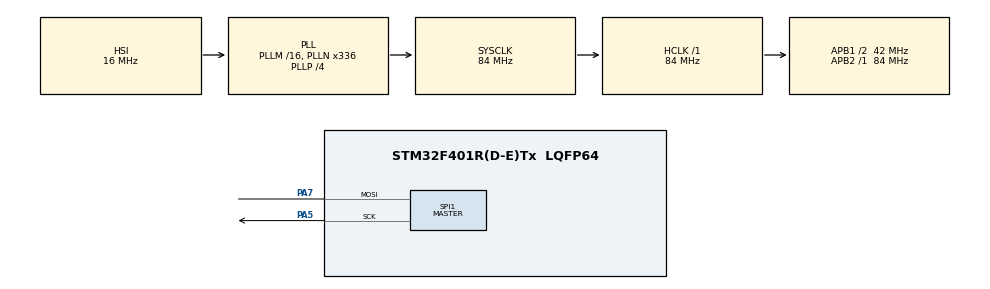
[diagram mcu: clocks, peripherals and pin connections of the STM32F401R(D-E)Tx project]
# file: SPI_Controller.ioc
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Mcu.Family=STM32F4
Mcu.Name=STM32F401R(D-E)Tx
Mcu.Package=LQFP64
NVIC.PriorityGroup=NVIC_PRIORITYGROUP_0
PA5.Mode=Simplex_Bidirectional_Master
PA5.Signal=SPI1_SCK
PA7.Mode=Simplex_Bidirectional_Master
PA7.Signal=SPI1_MOSI
ProjectManager.HeapSize=0x200
ProjectManager.StackSize=0x400
ProjectManager.TargetToolchain=STM32CubeIDE
RCC.48MHZClocksFreq_Value=48000000
RCC.AHBFreq_Value=84000000
RCC.APB1CLKDivider=RCC_HCLK_DIV2
RCC.APB1Freq_Value=42000000
RCC.APB1TimFreq_Value=84000000
RCC.APB2Freq_Value=84000000
RCC.APB2TimFreq_Value=84000000
RCC.CortexFreq_Value=84000000
RCC.HCLKFreq_Value=84000000
RCC.HSE_VALUE=8000000
RCC.HSI_VALUE=16000000
RCC.LSE_VALUE=32768
RCC.PLLN=336
RCC.PLLP=RCC_PLLP_DIV4
RCC.PLLQ=7
RCC.SYSCLKFreq_VALUE=84000000
RCC.SYSCLKSource=RCC_SYSCLKSOURCE_PLLCLK
RCC.VCOOutputFreq_Value=336000000
SPI1.Direction=SPI_DIRECTION_1LINE
SPI1.Mode=SPI_MODE_MASTER
SPI1.VirtualType=VM_MASTER
board=NUCLEO-F401RE

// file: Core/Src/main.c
/* USER CODE BEGIN Header */
/**
  ******************************************************************************
  * @file           : main.c
  * @brief          : Main program body
  ******************************************************************************
  * @attention
  *
  * Copyright (c) 2024 STMicroelectronics.
  * All rights reserved.
  *
  * This software is licensed under terms that can be found in the LICENSE file
  * in the root directory of this software component.
  * If no LICENSE file comes with this software, it is provided AS-IS.
  *
  ******************************************************************************
  */
/* USER CODE END Header */
#include "main.h"

/* USER CODE BEGIN Includes */
#include <string.h>

/* USER CODE END Includes */

SPI_HandleTypeDef hspi1;

void SystemClock_Config(void);
static void MX_GPIO_Init(void);
static void MX_SPI1_Init(void);

int main(void)
{

  /* MCU Configuration--------------------------------------------------------*/

  /* Reset of all peripherals, Initializes the Flash interface and the Systick. */
  HAL_Init();

  /* Configure the system clock */
  SystemClock_Config();

  /* Initialize all configured peripherals */
  MX_GPIO_Init();
  MX_SPI1_Init();

  /* Infinite loop */
  /* USER CODE BEGIN WHILE */
  char data[5] = "";
  uint8_t len_req = 0x3;
  uint8_t data_req = 0x2;
  uint8_t temp = 0x0;

  //(void)HAL_SPI_Transmit(&hspi1, &data, 1, 100000);

  //lets confirm SPI is not busy
 //while( ( SPI1->SR & SPI_SR_BSY ) == 1 );

  //for(int i = 0; i < 10000; i++) {};

  //lets confirm SPI is not busy
  //while( ( SPI1->SR & SPI_SR_BSY ) == 1 );
  //for(int i = 0; i < 10000000; i++) {};
  //(void)HAL_SPI_Transmit(&hspi1, &data_req, 1, 100000);
  //while( ( SPI1->SR & SPI_SR_BSY ) == 1 );

  SPI2->CR1 &= ~( 1 << SPI_CR1_SPE );
  SPI2->CR1 |= ( 1 << SPI_CR1_BIDIOE );
  SPI2->CR1 |= ( 1 << SPI_CR1_SPE );
  (void)HAL_SPI_Transmit(&hspi1, &len_req, 1, 100000);

  SPI2->CR1 &= ~( 1 << SPI_CR1_SPE );
  SPI2->CR1 &= ~( 1 << SPI_CR1_BIDIOE );
  SPI2->CR1 |= ( 1 << SPI_CR1_SPE );

  for(int i = 0; i < 10000000; i++) {};
  (void)HAL_SPI_Receive(&hspi1, (uint8_t *)data, 5, 100000);
  while( ( SPI1->SR & SPI_SR_BSY ) == 1 );

  while (1)
  {

    /* USER CODE END WHILE */

  }
}

void SystemClock_Config(void)
{
  RCC_OscInitTypeDef RCC_OscInitStruct = {0};
  RCC_ClkInitTypeDef RCC_ClkInitStruct = {0};

  /** Configure the main internal regulator output voltage
  */
  __HAL_RCC_PWR_CLK_ENABLE();
  __HAL_PWR_VOLTAGESCALING_CONFIG(PWR_REGULATOR_VOLTAGE_SCALE2);

  /** Initializes the RCC Oscillators according to the specified parameters
  * in the RCC_OscInitTypeDef structure.
  */
  RCC_OscInitStruct.OscillatorType = RCC_OSCILLATORTYPE_HSI;
  RCC_OscInitStruct.HSIState = RCC_HSI_ON;
  RCC_OscInitStruct.HSICalibrationValue = RCC_HSICALIBRATION_DEFAULT;
  RCC_OscInitStruct.PLL.PLLState = RCC_PLL_ON;
  RCC_OscInitStruct.PLL.PLLSource = RCC_PLLSOURCE_HSI;
  RCC_OscInitStruct.PLL.PLLM = 16;
  RCC_OscInitStruct.PLL.PLLN = 336;
  RCC_OscInitStruct.PLL.PLLP = RCC_PLLP_DIV4;
  RCC_OscInitStruct.PLL.PLLQ = 7;
  if (HAL_RCC_OscConfig(&RCC_OscInitStruct) != HAL_OK)
  {
    Error_Handler();
  }

  /** Initializes the CPU, AHB and APB buses clocks
  */
  RCC_ClkInitStruct.ClockType = RCC_CLOCKTYPE_HCLK|RCC_CLOCKTYPE_SYSCLK
                              |RCC_CLOCKTYPE_PCLK1|RCC_CLOCKTYPE_PCLK2;
  RCC_ClkInitStruct.SYSCLKSource = RCC_SYSCLKSOURCE_PLLCLK;
  RCC_ClkInitStruct.AHBCLKDivider = RCC_SYSCLK_DIV1;
  RCC_ClkInitStruct.APB1CLKDivider = RCC_HCLK_DIV2;
  RCC_ClkInitStruct.APB2CLKDivider = RCC_HCLK_DIV1;

  if (HAL_RCC_ClockConfig(&RCC_ClkInitStruct, FLASH_LATENCY_2) != HAL_OK)
  {
    Error_Handler();
  }
}

static void MX_SPI1_Init(void)
{

  /* SPI1 parameter configuration*/
  hspi1.Instance = SPI1;
  hspi1.Init.Mode = SPI_MODE_MASTER;
  hspi1.Init.Direction = SPI_DIRECTION_1LINE;
  hspi1.Init.DataSize = SPI_DATASIZE_8BIT;
  hspi1.Init.CLKPolarity = SPI_POLARITY_LOW;
  hspi1.Init.CLKPhase = SPI_PHASE_1EDGE;
  hspi1.Init.NSS = SPI_NSS_SOFT;
  hspi1.Init.BaudRatePrescaler = SPI_BAUDRATEPRESCALER_256;
  hspi1.Init.FirstBit = SPI_FIRSTBIT_MSB;
  hspi1.Init.TIMode = SPI_TIMODE_DISABLE;
  hspi1.Init.CRCCalculation = SPI_CRCCALCULATION_DISABLE;
  hspi1.Init.CRCPolynomial = 10;
  if (HAL_SPI_Init(&hspi1) != HAL_OK)
  {
    Error_Handler();
  }

}

static void MX_GPIO_Init(void)
{

  /* GPIO Ports Clock Enable */
  __HAL_RCC_GPIOA_CLK_ENABLE();

}

void Error_Handler(void)
{
  __disable_irq();
  while (1)
  {
  }
}
